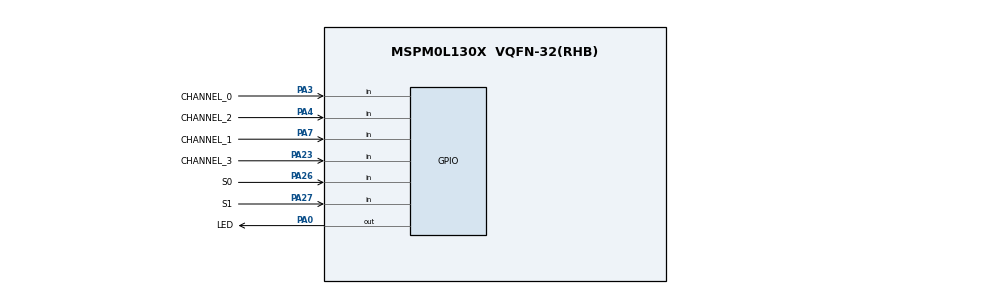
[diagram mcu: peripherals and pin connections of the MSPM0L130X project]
// @cliArgs --device "MSPM0L130X" --package "VQFN-32(RHB)" --part "Default"
// @cliArgs --board /ti/boards/LP_MSPM0L1306 --rtos nortos

/**
 * Import the modules used in this configuration.
 */
const GPIO  = scripting.addModule("/ti/driverlib/GPIO", {}, false);
const GPIO1 = GPIO.addInstance();
const GPIO2 = GPIO.addInstance();
const GPIO3 = GPIO.addInstance();

/**
 * Write custom configuration values to the imported modules.
 */
GPIO1.$name                          = "INPUT";
GPIO1.associatedPins.create(4);
GPIO1.associatedPins[0].$name        = "CHANNEL_0";
GPIO1.associatedPins[0].direction    = "INPUT";
GPIO1.associatedPins[0].ioStructure  = "SD";
GPIO1.associatedPins[0].interruptEn  = true;
GPIO1.associatedPins[0].polarity     = "RISE_FALL";
GPIO1.associatedPins[0].assignedPort = "PORTA";
GPIO1.associatedPins[0].pin.$assign  = "PA3";
GPIO1.associatedPins[1].$name        = "CHANNEL_1";
GPIO1.associatedPins[1].direction    = "INPUT";
GPIO1.associatedPins[1].ioStructure  = "SD";
GPIO1.associatedPins[1].assignedPort = "PORTA";
GPIO1.associatedPins[1].interruptEn  = true;
GPIO1.associatedPins[1].polarity     = "RISE_FALL";
GPIO1.associatedPins[1].pin.$assign  = "PA7";
GPIO1.associatedPins[2].$name        = "CHANNEL_2";
GPIO1.associatedPins[2].direction    = "INPUT";
GPIO1.associatedPins[2].ioStructure  = "SD";
GPIO1.associatedPins[2].assignedPort = "PORTA";
GPIO1.associatedPins[2].interruptEn  = true;
GPIO1.associatedPins[2].polarity     = "RISE_FALL";
GPIO1.associatedPins[2].pin.$assign  = "PA4";
GPIO1.associatedPins[3].$name        = "CHANNEL_3";
GPIO1.associatedPins[3].direction    = "INPUT";
GPIO1.associatedPins[3].ioStructure  = "SD";
GPIO1.associatedPins[3].assignedPort = "PORTA";
GPIO1.associatedPins[3].interruptEn  = true;
GPIO1.associatedPins[3].polarity     = "RISE_FALL";
GPIO1.associatedPins[3].pin.$assign  = "PA23";

const Board = scripting.addModule("/ti/driverlib/Board", {}, false);

GPIO2.$name                          = "SELECT";
GPIO2.associatedPins.create(2);
GPIO2.associatedPins[0].$name        = "S0";
GPIO2.associatedPins[0].direction    = "INPUT";
GPIO2.associatedPins[0].ioStructure  = "SD";
GPIO2.associatedPins[0].assignedPort = "PORTA";
GPIO2.associatedPins[0].interruptEn  = true;
GPIO2.associatedPins[0].polarity     = "RISE_FALL";
GPIO2.associatedPins[0].pin.$assign  = "PA26";
GPIO2.associatedPins[1].$name        = "S1";
GPIO2.associatedPins[1].direction    = "INPUT";
GPIO2.associatedPins[1].ioStructure  = "SD";
GPIO2.associatedPins[1].assignedPort = "PORTA";
GPIO2.associatedPins[1].interruptEn  = true;
GPIO2.associatedPins[1].polarity     = "RISE_FALL";
GPIO2.associatedPins[1].pin.$assign  = "PA27";

GPIO3.$name                         = "OUTPUT";
GPIO3.associatedPins[0].$name       = "LED";
GPIO3.associatedPins[0].pin.$assign = "PA0";

const SYSCTL = scripting.addModule("/ti/driverlib/SYSCTL", {}, false);
